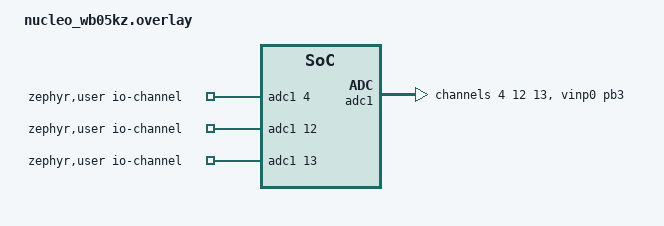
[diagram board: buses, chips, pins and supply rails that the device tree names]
/*
 * SPDX-License-Identifier: Apache-2.0
 *
 * Copyright (c) 2024 STMicroelectronics
 */

/ {
	zephyr,user {
		io-channels = <&adc1 4>, <&adc1 12>, <&adc1 13>;
	};
};

&adc1 {
	status = "okay";

	pinctrl-0 = <&adc1_vinp0_pb3>;
	pinctrl-names = "default";
	#address-cells = <1>;
	#size-cells = <0>;

	vinp0: channel@4 {
		reg = <4>;
		zephyr,gain = "ADC_GAIN_1";
		zephyr,reference = "ADC_REF_INTERNAL";
		zephyr,acquisition-time = <ADC_ACQ_TIME_DEFAULT>;
		zephyr,resolution = <12>;
	};

	adc_vbat_ch: channel@c {
		reg = <12>;
		zephyr,gain = "ADC_GAIN_1";
		zephyr,reference = "ADC_REF_VDD_1";
		zephyr,acquisition-time = <ADC_ACQ_TIME_DEFAULT>;
		zephyr,resolution = <12>;
	};

	adc_tempsensor_ch: channel@d {
		reg = <13>;
		zephyr,gain = "ADC_GAIN_1";
		zephyr,reference = "ADC_REF_VDD_1_3";
		zephyr,acquisition-time = <ADC_ACQ_TIME_DEFAULT>;
		zephyr,resolution = <12>;
	};
};
